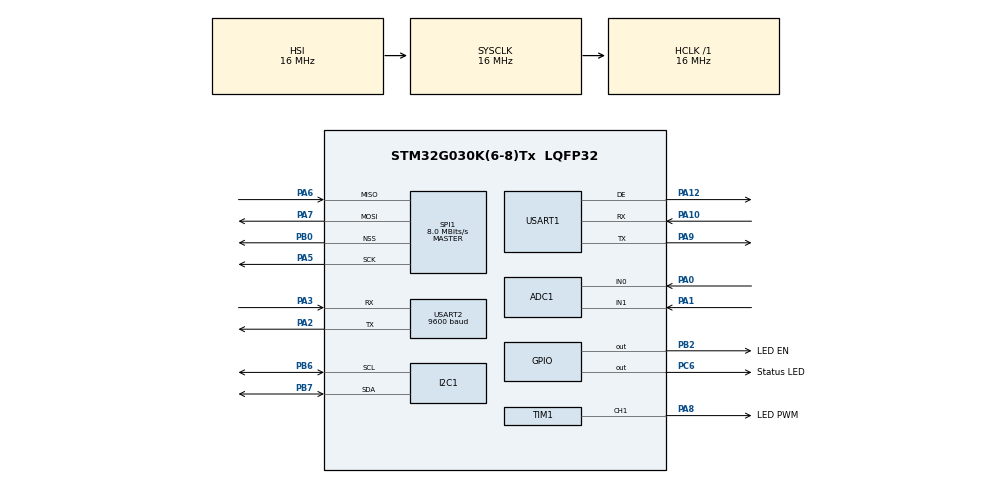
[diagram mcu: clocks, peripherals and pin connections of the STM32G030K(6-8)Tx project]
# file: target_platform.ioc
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ADC1.Channel-0\#ChannelRegularConversion=ADC_CHANNEL_0
ADC1.Channel-1\#ChannelRegularConversion=ADC_CHANNEL_0
ADC1.ContinuousConvMode=DISABLE
ADC1.DMAContinuousRequests=ENABLE
ADC1.EOCSelection=ADC_EOC_SEQ_CONV
ADC1.ExternalTrigConv=ADC_EXTERNALTRIG_T3_TRGO
ADC1.NbrOfConversion=2
ADC1.NbrOfConversionFlag=1
ADC1.Rank-0\#ChannelRegularConversion=1
ADC1.Rank-1\#ChannelRegularConversion=2
ADC1.SamplingTime-0\#ChannelRegularConversion=ADC_SAMPLINGTIME_COMMON_1
ADC1.SamplingTime-1\#ChannelRegularConversion=ADC_SAMPLINGTIME_COMMON_1
ADC1.SamplingTimeCommon1=ADC_SAMPLETIME_160CYCLES_5
ADC1.SamplingTimeCommon2=ADC_SAMPLETIME_160CYCLES_5
ADC1.SelectedChannel=ADC_CHANNEL_0|ADC_CHANNEL_1
ADC1.master=1
Dma.ADC1.0.Direction=DMA_PERIPH_TO_MEMORY
Dma.ADC1.0.EventEnable=DISABLE
Dma.ADC1.0.Instance=DMA1_Channel1
Dma.ADC1.0.MemDataAlignment=DMA_MDATAALIGN_WORD
Dma.ADC1.0.MemInc=DMA_MINC_ENABLE
Dma.ADC1.0.Mode=DMA_CIRCULAR
Dma.ADC1.0.PeriphDataAlignment=DMA_PDATAALIGN_WORD
Dma.ADC1.0.PeriphInc=DMA_PINC_DISABLE
Dma.ADC1.0.Polarity=HAL_DMAMUX_REQ_GEN_RISING
Dma.ADC1.0.Priority=DMA_PRIORITY_LOW
Dma.ADC1.0.RequestNumber=1
Dma.ADC1.0.SignalID=NONE
Dma.ADC1.0.SyncEnable=DISABLE
Dma.ADC1.0.SyncPolarity=HAL_DMAMUX_SYNC_NO_EVENT
Dma.ADC1.0.SyncRequestNumber=1
Dma.ADC1.0.SyncSignalID=NONE
Dma.Request0=ADC1
Dma.Request1=USART1_RX
Dma.Request2=USART1_TX
Dma.Request3=USART2_RX
Dma.Request4=USART2_TX
Dma.USART1_RX.1.Direction=DMA_PERIPH_TO_MEMORY
Dma.USART1_RX.1.EventEnable=DISABLE
Dma.USART1_RX.1.Instance=DMA1_Channel2
Dma.USART1_RX.1.MemDataAlignment=DMA_MDATAALIGN_BYTE
Dma.USART1_RX.1.MemInc=DMA_MINC_ENABLE
Dma.USART1_RX.1.Mode=DMA_NORMAL
Dma.USART1_RX.1.PeriphDataAlignment=DMA_PDATAALIGN_BYTE
Dma.USART1_RX.1.PeriphInc=DMA_PINC_DISABLE
Dma.USART1_RX.1.Polarity=HAL_DMAMUX_REQ_GEN_RISING
Dma.USART1_RX.1.Priority=DMA_PRIORITY_MEDIUM
Dma.USART1_RX.1.RequestNumber=1
Dma.USART1_RX.1.SignalID=NONE
Dma.USART1_RX.1.SyncEnable=DISABLE
Dma.USART1_RX.1.SyncPolarity=HAL_DMAMUX_SYNC_NO_EVENT
Dma.USART1_RX.1.SyncRequestNumber=1
Dma.USART1_RX.1.SyncSignalID=NONE
Dma.USART1_TX.2.Direction=DMA_MEMORY_TO_PERIPH
Dma.USART1_TX.2.EventEnable=DISABLE
Dma.USART1_TX.2.Instance=DMA1_Channel3
Dma.USART1_TX.2.MemDataAlignment=DMA_MDATAALIGN_BYTE
Dma.USART1_TX.2.MemInc=DMA_MINC_ENABLE
Dma.USART1_TX.2.Mode=DMA_NORMAL
Dma.USART1_TX.2.PeriphDataAlignment=DMA_PDATAALIGN_BYTE
Dma.USART1_TX.2.PeriphInc=DMA_PINC_DISABLE
Dma.USART1_TX.2.Polarity=HAL_DMAMUX_REQ_GEN_RISING
Dma.USART1_TX.2.Priority=DMA_PRIORITY_MEDIUM
Dma.USART1_TX.2.RequestNumber=1
Dma.USART1_TX.2.SignalID=NONE
Dma.USART1_TX.2.SyncEnable=DISABLE
Dma.USART1_TX.2.SyncPolarity=HAL_DMAMUX_SYNC_NO_EVENT
Dma.USART1_TX.2.SyncRequestNumber=1
Dma.USART1_TX.2.SyncSignalID=NONE
Dma.USART2_RX.3.Direction=DMA_PERIPH_TO_MEMORY
Dma.USART2_RX.3.EventEnable=DISABLE
Dma.USART2_RX.3.Instance=DMA1_Channel4
Dma.USART2_RX.3.MemDataAlignment=DMA_MDATAALIGN_BYTE
Dma.USART2_RX.3.MemInc=DMA_MINC_ENABLE
Dma.USART2_RX.3.Mode=DMA_NORMAL
Dma.USART2_RX.3.PeriphDataAlignment=DMA_PDATAALIGN_BYTE
Dma.USART2_RX.3.PeriphInc=DMA_PINC_DISABLE
Dma.USART2_RX.3.Polarity=HAL_DMAMUX_REQ_GEN_RISING
Dma.USART2_RX.3.Priority=DMA_PRIORITY_MEDIUM
Dma.USART2_RX.3.RequestNumber=1
Dma.USART2_RX.3.SignalID=NONE
Dma.USART2_RX.3.SyncEnable=DISABLE
Dma.USART2_RX.3.SyncPolarity=HAL_DMAMUX_SYNC_NO_EVENT
Dma.USART2_RX.3.SyncRequestNumber=1
Dma.USART2_RX.3.SyncSignalID=NONE
Dma.USART2_TX.4.Direction=DMA_MEMORY_TO_PERIPH
Dma.USART2_TX.4.EventEnable=DISABLE
Dma.USART2_TX.4.Instance=DMA1_Channel5
Dma.USART2_TX.4.MemDataAlignment=DMA_MDATAALIGN_BYTE
Dma.USART2_TX.4.MemInc=DMA_MINC_ENABLE
Dma.USART2_TX.4.Mode=DMA_NORMAL
Dma.USART2_TX.4.PeriphDataAlignment=DMA_PDATAALIGN_BYTE
Dma.USART2_TX.4.PeriphInc=DMA_PINC_DISABLE
Dma.USART2_TX.4.Polarity=HAL_DMAMUX_REQ_GEN_RISING
Dma.USART2_TX.4.Priority=DMA_PRIORITY_MEDIUM
Dma.USART2_TX.4.RequestNumber=1
Dma.USART2_TX.4.SignalID=NONE
Dma.USART2_TX.4.SyncEnable=DISABLE
Dma.USART2_TX.4.SyncPolarity=HAL_DMAMUX_SYNC_NO_EVENT
Dma.USART2_TX.4.SyncRequestNumber=1
Dma.USART2_TX.4.SyncSignalID=NONE
I2C1.Timing=0x00503D58
Mcu.Family=STM32G0
Mcu.Name=STM32G030K(6-8)Tx
Mcu.Package=LQFP32
NVIC.DMA1_Ch4_5_DMAMUX1_OVR_IRQn=true\:0\:0\:false\:false\:true\:false\:true\:true
NVIC.DMA1_Channel1_IRQn=true\:3\:0\:true\:false\:true\:false\:true\:true
NVIC.DMA1_Channel2_3_IRQn=true\:0\:0\:false\:false\:true\:false\:true\:true
NVIC.TIM14_IRQn=true\:0\:0\:false\:false\:true\:true\:true\:true
NVIC.TIM16_IRQn=true\:0\:0\:false\:false\:true\:true\:true\:true
NVIC.TIM3_IRQn=true\:0\:0\:false\:false\:true\:true\:true\:true
PA0.Mode=IN0
PA0.Signal=ADC1_IN0
PA1.Mode=IN1
PA1.Signal=ADC1_IN1
PA10.Mode=Asynchronous
PA10.Signal=USART1_RX
PA12\ [PA10].Mode=Hardware Flow Control (RS485)
PA12\ [PA10].Signal=USART1_DE
PA13.Mode=Serial_Wire
PA13.Signal=SYS_SWDIO
PA14-BOOT0.Mode=Serial_Wire
PA14-BOOT0.Signal=SYS_SWCLK
PA2.Mode=Asynchronous
PA2.Signal=USART2_TX
PA3.Mode=Asynchronous
PA3.Signal=USART2_RX
PA5.Mode=Full_Duplex_Master
PA5.Signal=SPI1_SCK
PA6.Mode=Full_Duplex_Master
PA6.Signal=SPI1_MISO
PA7.Mode=Full_Duplex_Master
PA7.Signal=SPI1_MOSI
PA8.GPIO_Label=LED PWM
PA8.Signal=S_TIM1_CH1
PA9.Mode=Asynchronous
PA9.Signal=USART1_TX
PB0.Mode=NSS_Signal_Hard_Output
PB0.Signal=SPI1_NSS
PB2.GPIO_Label=LED EN
PB2.Signal=GPIO_Output
PB6.Mode=I2C
PB6.Signal=I2C1_SCL
PB7.Mode=I2C
PB7.Signal=I2C1_SDA
PC14-OSC32_IN\ (PC14).Mode=HSE-External-Clock-Source
PC14-OSC32_IN\ (PC14).Signal=RCC_OSC_IN
PC6.GPIO_Label=Status LED
PC6.Signal=GPIO_Output
ProjectManager.HeapSize=0x200
ProjectManager.StackSize=0x400
ProjectManager.TargetToolchain=CMake
RCC.AHBFreq_Value=16000000
RCC.CortexFreq_Value=16000000
RCC.EXTERNAL_CLOCK_VALUE=12288000
RCC.HCLKFreq_Value=16000000
RCC.HSE_VALUE=8000000
RCC.HSI_VALUE=16000000
RCC.LSE_VALUE=32768
RCC.SYSCLKFreq_VALUE=16000000
RCC.VCOOutputFreq_Value=128000000
SH.S_TIM1_CH1.0=TIM1_CH1,PWM Generation1 CH1
SPI1.CalculateBaudRate=8.0 MBits/s
SPI1.Direction=SPI_DIRECTION_2LINES
SPI1.Mode=SPI_MODE_MASTER
SPI1.VirtualNSS=VM_NSSHARD
SPI1.VirtualType=VM_MASTER
TIM1.Channel-PWM\ Generation1\ CH1=TIM_CHANNEL_1
TIM14.Channel=TIM_CHANNEL_1
TIM14.Period=62499
TIM14.Prescaler=255
TIM14.Pulse=60
TIM16.Channel=TIM_CHANNEL_1
TIM16.Period=62499
TIM16.Prescaler=127
TIM3.Channel-Output\ Compare1\ No\ Output=TIM_CHANNEL_1
TIM3.Period=49999
TIM3.Prescaler=31
TIM3.Pulse-Output\ Compare1\ No\ Output=60
TIM3.TIM_MasterOutputTrigger=TIM_TRGO_ENABLE
USART1.VirtualMode-Asynchronous=VM_ASYNC
USART1.VirtualMode-Hardware\ Flow\ Control\ (RS485)=VM_ASYNC
USART2.BaudRate=9600
USART2.VirtualMode-Asynchronous=VM_ASYNC
VP_RTC_VS_RTC_Activate.Mode=RTC_Enabled
VP_RTC_VS_RTC_Calendar.Mode=RTC_Calendar
VP_TIM14_VS_ClockSourceINT.Mode=Enable_Timer
VP_TIM14_VS_no_output1.Mode=Output Compare1 No Output
VP_TIM16_VS_ClockSourceINT.Mode=Enable_Timer
VP_TIM16_VS_no_output1.Mode=Output Compare1 No Output
VP_TIM1_VS_ClockSourceINT.Mode=Internal
VP_TIM3_VS_no_output1.Mode=Output Compare1 No Output
board=custom

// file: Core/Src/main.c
/* USER CODE BEGIN Header */
/**
 ******************************************************************************
 * @file           : main.c
 * @brief          : Main program body
 ******************************************************************************
 * @attention
 *
 * Copyright (c) 2026 STMicroelectronics.
 * All rights reserved.
 *
 * This software is licensed under terms that can be found in the LICENSE file
 * in the root directory of this software component.
 * If no LICENSE file comes with this software, it is provided AS-IS.
 *
 ******************************************************************************
 */
/* USER CODE END Header */
#include "main.h"

/* USER CODE BEGIN Includes */
#include "bsp_spi.h"
#include "led_pwm_control.h"
/* USER CODE END Includes */

ADC_HandleTypeDef hadc1;
DMA_HandleTypeDef hdma_adc1;

I2C_HandleTypeDef hi2c1;

RTC_HandleTypeDef hrtc;

SPI_HandleTypeDef hspi1;

TIM_HandleTypeDef htim1;
TIM_HandleTypeDef htim3;
TIM_HandleTypeDef htim14;
TIM_HandleTypeDef htim16;

UART_HandleTypeDef huart1;
UART_HandleTypeDef huart2;
DMA_HandleTypeDef hdma_usart1_rx;
DMA_HandleTypeDef hdma_usart1_tx;
DMA_HandleTypeDef hdma_usart2_rx;
DMA_HandleTypeDef hdma_usart2_tx;

void SystemClock_Config(void);
static void MX_GPIO_Init(void);
static void MX_DMA_Init(void);
static void MX_ADC1_Init(void);
static void MX_I2C1_Init(void);
static void MX_SPI1_Init(void);
static void MX_TIM1_Init(void);
static void MX_TIM3_Init(void);
static void MX_USART1_UART_Init(void);
static void MX_USART2_UART_Init(void);
static void MX_RTC_Init(void);
static void MX_TIM14_Init(void);
static void MX_TIM16_Init(void);

/* USER CODE BEGIN 0 */
ir_led_pwm_t ir_led;

/* USER CODE END 0 */

int main(void)
{

    /* MCU Configuration--------------------------------------------------------*/

    /* Reset of all peripherals, Initializes the Flash interface and the Systick. */
    HAL_Init();

    /* Configure the system clock */
    SystemClock_Config();

    /* Initialize all configured peripherals */
    MX_GPIO_Init();
    MX_DMA_Init();
    MX_ADC1_Init();
    MX_I2C1_Init();
    MX_SPI1_Init();
    MX_TIM1_Init();
    MX_TIM3_Init();
    MX_USART1_UART_Init();
    MX_USART2_UART_Init();
    MX_RTC_Init();
    MX_TIM14_Init();
    MX_TIM16_Init();
    /* USER CODE BEGIN 2 */
    ir_led_pwm_init(&ir_led, BSP_PWM_IR_LED);

    /* USER CODE END 2 */

    /* Infinite loop */
    while (1)
    {

    }
}

void SystemClock_Config(void)
{
    RCC_OscInitTypeDef RCC_OscInitStruct = {0};
    RCC_ClkInitTypeDef RCC_ClkInitStruct = {0};

    /** Configure the main internal regulator output voltage
     */
    HAL_PWREx_ControlVoltageScaling(PWR_REGULATOR_VOLTAGE_SCALE1);

    /** Initializes the RCC Oscillators according to the specified parameters
     * in the RCC_OscInitTypeDef structure.
     */
    RCC_OscInitStruct.OscillatorType = RCC_OSCILLATORTYPE_HSI | RCC_OSCILLATORTYPE_LSI;
    RCC_OscInitStruct.HSIState = RCC_HSI_ON;
    RCC_OscInitStruct.HSIDiv = RCC_HSI_DIV1;
    RCC_OscInitStruct.HSICalibrationValue = RCC_HSICALIBRATION_DEFAULT;
    RCC_OscInitStruct.LSIState = RCC_LSI_ON;
    RCC_OscInitStruct.PLL.PLLState = RCC_PLL_NONE;
    if (HAL_RCC_OscConfig(&RCC_OscInitStruct) != HAL_OK)
    {
        Error_Handler();
    }

    /** Initializes the CPU, AHB and APB buses clocks
     */
    RCC_ClkInitStruct.ClockType = RCC_CLOCKTYPE_HCLK | RCC_CLOCKTYPE_SYSCLK | RCC_CLOCKTYPE_PCLK1;
    RCC_ClkInitStruct.SYSCLKSource = RCC_SYSCLKSOURCE_HSI;
    RCC_ClkInitStruct.AHBCLKDivider = RCC_SYSCLK_DIV1;
    RCC_ClkInitStruct.APB1CLKDivider = RCC_HCLK_DIV1;

    if (HAL_RCC_ClockConfig(&RCC_ClkInitStruct, FLASH_LATENCY_0) != HAL_OK)
    {
        Error_Handler();
    }
}

static void MX_ADC1_Init(void)
{

    ADC_ChannelConfTypeDef sConfig = {0};

    /** Configure the global features of the ADC (Clock, Resolution, Data Alignment and number of
     * conversion)
     */
    hadc1.Instance = ADC1;
    hadc1.Init.ClockPrescaler = ADC_CLOCK_SYNC_PCLK_DIV2;
    hadc1.Init.Resolution = ADC_RESOLUTION_12B;
    hadc1.Init.DataAlign = ADC_DATAALIGN_RIGHT;
    hadc1.Init.ScanConvMode = ADC_SCAN_ENABLE;
    hadc1.Init.EOCSelection = ADC_EOC_SEQ_CONV;
    hadc1.Init.LowPowerAutoWait = DISABLE;
    hadc1.Init.LowPowerAutoPowerOff = DISABLE;
    hadc1.Init.ContinuousConvMode = DISABLE;
    hadc1.Init.NbrOfConversion = 2;
    hadc1.Init.DiscontinuousConvMode = DISABLE;
    hadc1.Init.ExternalTrigConv = ADC_EXTERNALTRIG_T3_TRGO;
    hadc1.Init.ExternalTrigConvEdge = ADC_EXTERNALTRIGCONVEDGE_RISING;
    hadc1.Init.DMAContinuousRequests = ENABLE;
    hadc1.Init.Overrun = ADC_OVR_DATA_PRESERVED;
    hadc1.Init.SamplingTimeCommon1 = ADC_SAMPLETIME_160CYCLES_5;
    hadc1.Init.SamplingTimeCommon2 = ADC_SAMPLETIME_160CYCLES_5;
    hadc1.Init.OversamplingMode = DISABLE;
    hadc1.Init.TriggerFrequencyMode = ADC_TRIGGER_FREQ_HIGH;
    if (HAL_ADC_Init(&hadc1) != HAL_OK)
    {
        Error_Handler();
    }

    /** Configure Regular Channel
     */
    sConfig.Channel = ADC_CHANNEL_0;
    sConfig.Rank = ADC_REGULAR_RANK_1;
    sConfig.SamplingTime = ADC_SAMPLINGTIME_COMMON_1;
    if (HAL_ADC_ConfigChannel(&hadc1, &sConfig) != HAL_OK)
    {
        Error_Handler();
    }

    /** Configure Regular Channel
     */
    sConfig.Rank = ADC_REGULAR_RANK_2;
    if (HAL_ADC_ConfigChannel(&hadc1, &sConfig) != HAL_OK)
    {
        Error_Handler();
    }
}

static void MX_I2C1_Init(void)
{

    hi2c1.Instance = I2C1;
    hi2c1.Init.Timing = 0x00503D58;
    hi2c1.Init.OwnAddress1 = 0;
    hi2c1.Init.AddressingMode = I2C_ADDRESSINGMODE_7BIT;
    hi2c1.Init.DualAddressMode = I2C_DUALADDRESS_DISABLE;
    hi2c1.Init.OwnAddress2 = 0;
    hi2c1.Init.OwnAddress2Masks = I2C_OA2_NOMASK;
    hi2c1.Init.GeneralCallMode = I2C_GENERALCALL_DISABLE;
    hi2c1.Init.NoStretchMode = I2C_NOSTRETCH_DISABLE;
    if (HAL_I2C_Init(&hi2c1) != HAL_OK)
    {
        Error_Handler();
    }

    /** Configure Analogue filter
     */
    if (HAL_I2CEx_ConfigAnalogFilter(&hi2c1, I2C_ANALOGFILTER_ENABLE) != HAL_OK)
    {
        Error_Handler();
    }

    /** Configure Digital filter
     */
    if (HAL_I2CEx_ConfigDigitalFilter(&hi2c1, 0) != HAL_OK)
    {
        Error_Handler();
    }
}

static void MX_RTC_Init(void)
{

    RTC_TimeTypeDef sTime = {0};
    RTC_DateTypeDef sDate = {0};

    /** Initialize RTC Only
     */
    hrtc.Instance = RTC;
    hrtc.Init.HourFormat = RTC_HOURFORMAT_24;
    hrtc.Init.AsynchPrediv = 127;
    hrtc.Init.SynchPrediv = 255;
    hrtc.Init.OutPut = RTC_OUTPUT_DISABLE;
    hrtc.Init.OutPutRemap = RTC_OUTPUT_REMAP_NONE;
    hrtc.Init.OutPutPolarity = RTC_OUTPUT_POLARITY_HIGH;
    hrtc.Init.OutPutType = RTC_OUTPUT_TYPE_OPENDRAIN;
    hrtc.Init.OutPutPullUp = RTC_OUTPUT_PULLUP_NONE;
    if (HAL_RTC_Init(&hrtc) != HAL_OK)
    {
        Error_Handler();
    }

    /** Initialize RTC and set the Time and Date
     */
    sTime.Hours = 0x0;
    sTime.Minutes = 0x0;
    sTime.Seconds = 0x0;
    sTime.SubSeconds = 0x0;
    sTime.DayLightSaving = RTC_DAYLIGHTSAVING_NONE;
    sTime.StoreOperation = RTC_STOREOPERATION_RESET;
    if (HAL_RTC_SetTime(&hrtc, &sTime, RTC_FORMAT_BCD) != HAL_OK)
    {
        Error_Handler();
    }
    sDate.WeekDay = RTC_WEEKDAY_MONDAY;
    sDate.Month = RTC_MONTH_JANUARY;
    sDate.Date = 0x1;
    sDate.Year = 0x0;

    if (HAL_RTC_SetDate(&hrtc, &sDate, RTC_FORMAT_BCD) != HAL_OK)
    {
        Error_Handler();
    }
}

static void MX_SPI1_Init(void)
{

    /* SPI1 parameter configuration*/
    hspi1.Instance = SPI1;
    hspi1.Init.Mode = SPI_MODE_MASTER;
    hspi1.Init.Direction = SPI_DIRECTION_2LINES;
    hspi1.Init.DataSize = SPI_DATASIZE_8BIT;
    hspi1.Init.CLKPolarity = SPI_POLARITY_LOW;
    hspi1.Init.CLKPhase = SPI_PHASE_1EDGE;
    hspi1.Init.NSS = SPI_NSS_HARD_OUTPUT;
    hspi1.Init.BaudRatePrescaler = SPI_BAUDRATEPRESCALER_2;
    hspi1.Init.FirstBit = SPI_FIRSTBIT_MSB;
    hspi1.Init.TIMode = SPI_TIMODE_DISABLE;
    hspi1.Init.CRCCalculation = SPI_CRCCALCULATION_DISABLE;
    hspi1.Init.CRCPolynomial = 7;
    hspi1.Init.CRCLength = SPI_CRC_LENGTH_DATASIZE;
    hspi1.Init.NSSPMode = SPI_NSS_PULSE_ENABLE;
    if (HAL_SPI_Init(&hspi1) != HAL_OK)
    {
        Error_Handler();
    }
}

static void MX_TIM1_Init(void)
{

    TIM_ClockConfigTypeDef sClockSourceConfig = {0};
    TIM_MasterConfigTypeDef sMasterConfig = {0};
    TIM_OC_InitTypeDef sConfigOC = {0};
    TIM_BreakDeadTimeConfigTypeDef sBreakDeadTimeConfig = {0};

    htim1.Instance = TIM1;
    htim1.Init.Prescaler = 0;
    htim1.Init.CounterMode = TIM_COUNTERMODE_UP;
    htim1.Init.Period = 65535;
    htim1.Init.ClockDivision = TIM_CLOCKDIVISION_DIV1;
    htim1.Init.RepetitionCounter = 0;
    htim1.Init.AutoReloadPreload = TIM_AUTORELOAD_PRELOAD_DISABLE;
    if (HAL_TIM_Base_Init(&htim1) != HAL_OK)
    {
        Error_Handler();
    }
    sClockSourceConfig.ClockSource = TIM_CLOCKSOURCE_INTERNAL;
    if (HAL_TIM_ConfigClockSource(&htim1, &sClockSourceConfig) != HAL_OK)
    {
        Error_Handler();
    }
    if (HAL_TIM_PWM_Init(&htim1) != HAL_OK)
    {
        Error_Handler();
    }
    sMasterConfig.MasterOutputTrigger = TIM_TRGO_RESET;
    sMasterConfig.MasterOutputTrigger2 = TIM_TRGO2_RESET;
    sMasterConfig.MasterSlaveMode = TIM_MASTERSLAVEMODE_DISABLE;
    if (HAL_TIMEx_MasterConfigSynchronization(&htim1, &sMasterConfig) != HAL_OK)
    {
        Error_Handler();
    }
    sConfigOC.OCMode = TIM_OCMODE_PWM1;
    sConfigOC.Pulse = 0;
    sConfigOC.OCPolarity = TIM_OCPOLARITY_HIGH;
    sConfigOC.OCNPolarity = TIM_OCNPOLARITY_HIGH;
    sConfigOC.OCFastMode = TIM_OCFAST_DISABLE;
    sConfigOC.OCIdleState = TIM_OCIDLESTATE_RESET;
    sConfigOC.OCNIdleState = TIM_OCNIDLESTATE_RESET;
    if (HAL_TIM_PWM_ConfigChannel(&htim1, &sConfigOC, TIM_CHANNEL_1) != HAL_OK)
    {
        Error_Handler();
    }
    sBreakDeadTimeConfig.OffStateRunMode = TIM_OSSR_DISABLE;
    sBreakDeadTimeConfig.OffStateIDLEMode = TIM_OSSI_DISABLE;
    sBreakDeadTimeConfig.LockLevel = TIM_LOCKLEVEL_OFF;
    sBreakDeadTimeConfig.DeadTime = 0;
    sBreakDeadTimeConfig.BreakState = TIM_BREAK_DISABLE;
    sBreakDeadTimeConfig.BreakPolarity = TIM_BREAKPOLARITY_HIGH;
    sBreakDeadTimeConfig.BreakFilter = 0;
    sBreakDeadTimeConfig.BreakAFMode = TIM_BREAK_AFMODE_INPUT;
    sBreakDeadTimeConfig.Break2State = TIM_BREAK2_DISABLE;
    sBreakDeadTimeConfig.Break2Polarity = TIM_BREAK2POLARITY_HIGH;
    sBreakDeadTimeConfig.Break2Filter = 0;
    sBreakDeadTimeConfig.Break2AFMode = TIM_BREAK_AFMODE_INPUT;
    sBreakDeadTimeConfig.AutomaticOutput = TIM_AUTOMATICOUTPUT_DISABLE;
    if (HAL_TIMEx_ConfigBreakDeadTime(&htim1, &sBreakDeadTimeConfig) != HAL_OK)
    {
        Error_Handler();
    }
    HAL_TIM_MspPostInit(&htim1);
}

static void MX_TIM3_Init(void)
{

    TIM_MasterConfigTypeDef sMasterConfig = {0};
    TIM_OC_InitTypeDef sConfigOC = {0};

    htim3.Instance = TIM3;
    htim3.Init.Prescaler = 31;
    htim3.Init.CounterMode = TIM_COUNTERMODE_UP;
    htim3.Init.Period = 49999;
    htim3.Init.ClockDivision = TIM_CLOCKDIVISION_DIV1;
    htim3.Init.AutoReloadPreload = TIM_AUTORELOAD_PRELOAD_DISABLE;
    if (HAL_TIM_OC_Init(&htim3) != HAL_OK)
    {
        Error_Handler();
    }
    sMasterConfig.MasterOutputTrigger = TIM_TRGO_ENABLE;
    sMasterConfig.MasterSlaveMode = TIM_MASTERSLAVEMODE_DISABLE;
    if (HAL_TIMEx_MasterConfigSynchronization(&htim3, &sMasterConfig) != HAL_OK)
    {
        Error_Handler();
    }
    sConfigOC.OCMode = TIM_OCMODE_TIMING;
    sConfigOC.Pulse = 60;
    sConfigOC.OCPolarity = TIM_OCPOLARITY_HIGH;
    sConfigOC.OCFastMode = TIM_OCFAST_DISABLE;
    if (HAL_TIM_OC_ConfigChannel(&htim3, &sConfigOC, TIM_CHANNEL_1) != HAL_OK)
    {
        Error_Handler();
    }
}

static void MX_TIM14_Init(void)
{

    TIM_OC_InitTypeDef sConfigOC = {0};

    htim14.Instance = TIM14;
    htim14.Init.Prescaler = 255;
    htim14.Init.CounterMode = TIM_COUNTERMODE_UP;
    htim14.Init.Period = 62499;
    htim14.Init.ClockDivision = TIM_CLOCKDIVISION_DIV1;
    htim14.Init.AutoReloadPreload = TIM_AUTORELOAD_PRELOAD_DISABLE;
    if (HAL_TIM_Base_Init(&htim14) != HAL_OK)
    {
        Error_Handler();
    }
    if (HAL_TIM_OC_Init(&htim14) != HAL_OK)
    {
        Error_Handler();
    }
    sConfigOC.OCMode = TIM_OCMODE_TIMING;
    sConfigOC.Pulse = 60;
    sConfigOC.OCPolarity = TIM_OCPOLARITY_HIGH;
    sConfigOC.OCFastMode = TIM_OCFAST_DISABLE;
    if (HAL_TIM_OC_ConfigChannel(&htim14, &sConfigOC, TIM_CHANNEL_1) != HAL_OK)
    {
        Error_Handler();
    }
}

static void MX_TIM16_Init(void)
{

    TIM_OC_InitTypeDef sConfigOC = {0};
    TIM_BreakDeadTimeConfigTypeDef sBreakDeadTimeConfig = {0};

    htim16.Instance = TIM16;
    htim16.Init.Prescaler = 127;
    htim16.Init.CounterMode = TIM_COUNTERMODE_UP;
    htim16.Init.Period = 62499;
    htim16.Init.ClockDivision = TIM_CLOCKDIVISION_DIV1;
    htim16.Init.RepetitionCounter = 0;
    htim16.Init.AutoReloadPreload = TIM_AUTORELOAD_PRELOAD_DISABLE;
    if (HAL_TIM_Base_Init(&htim16) != HAL_OK)
    {
        Error_Handler();
    }
    if (HAL_TIM_OC_Init(&htim16) != HAL_OK)
    {
        Error_Handler();
    }
    sConfigOC.OCMode = TIM_OCMODE_TIMING;
    sConfigOC.Pulse = 0;
    sConfigOC.OCPolarity = TIM_OCPOLARITY_HIGH;
    sConfigOC.OCNPolarity = TIM_OCNPOLARITY_HIGH;
    sConfigOC.OCFastMode = TIM_OCFAST_DISABLE;
    sConfigOC.OCIdleState = TIM_OCIDLESTATE_RESET;
    sConfigOC.OCNIdleState = TIM_OCNIDLESTATE_RESET;
    if (HAL_TIM_OC_ConfigChannel(&htim16, &sConfigOC, TIM_CHANNEL_1) != HAL_OK)
    {
        Error_Handler();
    }
    sBreakDeadTimeConfig.OffStateRunMode = TIM_OSSR_DISABLE;
    sBreakDeadTimeConfig.OffStateIDLEMode = TIM_OSSI_DISABLE;
    sBreakDeadTimeConfig.LockLevel = TIM_LOCKLEVEL_OFF;
    sBreakDeadTimeConfig.DeadTime = 0;
    sBreakDeadTimeConfig.BreakState = TIM_BREAK_DISABLE;
    sBreakDeadTimeConfig.BreakPolarity = TIM_BREAKPOLARITY_HIGH;
    sBreakDeadTimeConfig.BreakFilter = 0;
    sBreakDeadTimeConfig.AutomaticOutput = TIM_AUTOMATICOUTPUT_DISABLE;
    if (HAL_TIMEx_ConfigBreakDeadTime(&htim16, &sBreakDeadTimeConfig) != HAL_OK)
    {
        Error_Handler();
    }
}

static void MX_USART1_UART_Init(void)
{

    huart1.Instance = USART1;
    huart1.Init.BaudRate = 115200;
    huart1.Init.WordLength = UART_WORDLENGTH_8B;
    huart1.Init.StopBits = UART_STOPBITS_1;
    huart1.Init.Parity = UART_PARITY_NONE;
    huart1.Init.Mode = UART_MODE_TX_RX;
    huart1.Init.HwFlowCtl = UART_HWCONTROL_NONE;
    huart1.Init.OverSampling = UART_OVERSAMPLING_16;
    huart1.Init.OneBitSampling = UART_ONE_BIT_SAMPLE_DISABLE;
    huart1.Init.ClockPrescaler = UART_PRESCALER_DIV1;
    huart1.AdvancedInit.AdvFeatureInit = UART_ADVFEATURE_NO_INIT;
    if (HAL_RS485Ex_Init(&huart1, UART_DE_POLARITY_HIGH, 0, 0) != HAL_OK)
    {
        Error_Handler();
    }
    if (HAL_UARTEx_SetTxFifoThreshold(&huart1, UART_TXFIFO_THRESHOLD_1_8) != HAL_OK)
    {
        Error_Handler();
    }
    if (HAL_UARTEx_SetRxFifoThreshold(&huart1, UART_RXFIFO_THRESHOLD_1_8) != HAL_OK)
    {
        Error_Handler();
    }
    if (HAL_UARTEx_DisableFifoMode(&huart1) != HAL_OK)
    {
        Error_Handler();
    }
}

static void MX_USART2_UART_Init(void)
{

    huart2.Instance = USART2;
    huart2.Init.BaudRate = 9600;
    huart2.Init.WordLength = UART_WORDLENGTH_8B;
    huart2.Init.StopBits = UART_STOPBITS_1;
    huart2.Init.Parity = UART_PARITY_NONE;
    huart2.Init.Mode = UART_MODE_TX_RX;
    huart2.Init.HwFlowCtl = UART_HWCONTROL_NONE;
    huart2.Init.OverSampling = UART_OVERSAMPLING_16;
    huart2.Init.OneBitSampling = UART_ONE_BIT_SAMPLE_DISABLE;
    huart2.Init.ClockPrescaler = UART_PRESCALER_DIV1;
    huart2.AdvancedInit.AdvFeatureInit = UART_ADVFEATURE_NO_INIT;
    if (HAL_UART_Init(&huart2) != HAL_OK)
    {
        Error_Handler();
    }
}

static void MX_DMA_Init(void)
{
    /* DMA controller clock enable */
    __HAL_RCC_DMA1_CLK_ENABLE();

    /* DMA interrupt init */
    /* DMA1_Channel1_IRQn interrupt configuration */
    HAL_NVIC_SetPriority(DMA1_Channel1_IRQn, 3, 0);
    HAL_NVIC_EnableIRQ(DMA1_Channel1_IRQn);
    /* DMA1_Channel2_3_IRQn interrupt configuration */
    HAL_NVIC_SetPriority(DMA1_Channel2_3_IRQn, 0, 0);
    HAL_NVIC_EnableIRQ(DMA1_Channel2_3_IRQn);
    /* DMA1_Ch4_5_DMAMUX1_OVR_IRQn interrupt configuration */
    HAL_NVIC_SetPriority(DMA1_Ch4_5_DMAMUX1_OVR_IRQn, 0, 0);
    HAL_NVIC_EnableIRQ(DMA1_Ch4_5_DMAMUX1_OVR_IRQn);
}

static void MX_GPIO_Init(void)
{
    GPIO_InitTypeDef GPIO_InitStruct = {0};

    /* GPIO Ports Clock Enable */
    __HAL_RCC_GPIOC_CLK_ENABLE();
    __HAL_RCC_GPIOA_CLK_ENABLE();
    __HAL_RCC_GPIOB_CLK_ENABLE();

    /*Configure GPIO pin Output Level */
    HAL_GPIO_WritePin(LED_EN_GPIO_Port, LED_EN_Pin, GPIO_PIN_RESET);

    /*Configure GPIO pin Output Level */
    HAL_GPIO_WritePin(Status_LED_GPIO_Port, Status_LED_Pin, GPIO_PIN_RESET);

    /*Configure GPIO pin : LED_EN_Pin */
    GPIO_InitStruct.Pin = LED_EN_Pin;
    GPIO_InitStruct.Mode = GPIO_MODE_OUTPUT_PP;
    GPIO_InitStruct.Pull = GPIO_NOPULL;
    GPIO_InitStruct.Speed = GPIO_SPEED_FREQ_LOW;
    HAL_GPIO_Init(LED_EN_GPIO_Port, &GPIO_InitStruct);

    /*Configure GPIO pin : Status_LED_Pin */
    GPIO_InitStruct.Pin = Status_LED_Pin;
    GPIO_InitStruct.Mode = GPIO_MODE_OUTPUT_PP;
    GPIO_InitStruct.Pull = GPIO_NOPULL;
    GPIO_InitStruct.Speed = GPIO_SPEED_FREQ_LOW;
    HAL_GPIO_Init(Status_LED_GPIO_Port, &GPIO_InitStruct);

}

/* USER CODE BEGIN 4 */

// pipe the spi handle to the pipe/arbiter that will call the associated callback function
void HAL_SPI_TxCpltCallback(SPI_HandleTypeDef* hspi) {
    bsp_spi_tx_dma_cb_pipe(hspi);
}

/* USER CODE END 4 */

void Error_Handler(void)
{
    __disable_irq();
    while (1)
    {
    }
}
